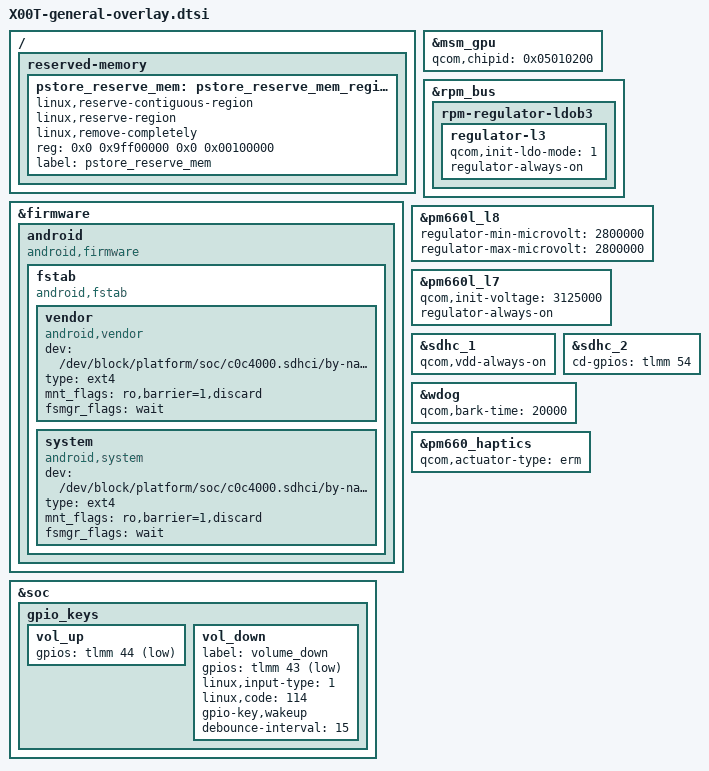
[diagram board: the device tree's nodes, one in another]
/* SPDX-License-Identifier: GPL-2.0 */

/ {
	reserved-memory {
		pstore_reserve_mem: pstore_reserve_mem_region@0 {
				linux,reserve-contiguous-region;
				linux,reserve-region;
				linux,remove-completely;
				reg = <0x0 0x9ff00000 0x0 0x00100000>;
				label = "pstore_reserve_mem";
		};
	};
};

&firmware {
	android {
		compatible = "android,firmware";
		fstab {
			compatible = "android,fstab";
			vendor {
				compatible = "android,vendor";
				dev = "/dev/block/platform/soc/c0c4000.sdhci/by-name/vendor";
				type = "ext4";
				mnt_flags = "ro,barrier=1,discard";
				fsmgr_flags = "wait";
				status = "ok";
			};
			system {
				compatible = "android,system";
				dev = "/dev/block/platform/soc/c0c4000.sdhci/by-name/system";
				type = "ext4";
				mnt_flags = "ro,barrier=1,discard";
				fsmgr_flags = "wait";
				status = "ok";
			};
		};	
	};
};

&msm_gpu {
	qcom,chipid = <0x05010200>;	
};	

&rpm_bus {
	rpm-regulator-ldob3 {
		regulator-l3 {
			qcom,init-ldo-mode = <1>;
			regulator-always-on;
		};
	};
};

&pm660l_l8 {
	regulator-min-microvolt = <2800000>;
	regulator-max-microvolt = <2800000>;
};

&pm660l_l7 {
	/delete-property/ parent-supply;

	qcom,init-voltage = <3125000>;
	regulator-always-on;
};

&sdhc_1 {
	qcom,vdd-always-on;
};

&sdhc_2 {
	cd-gpios = <&tlmm 54 0x0>;
};

&wdog {
	qcom,bark-time = <20000>;
};

&pm660_haptics {
	qcom,actuator-type = "erm";
};

&soc {
	gpio_keys {
		vol_up {
			gpios = <&tlmm 44 0x1>;
		};

		vol_down {
			label = "volume_down";
			gpios = <&tlmm 43 0x1>;
			linux,input-type = <1>;
			linux,code = <114>;
			gpio-key,wakeup;
			debounce-interval = <15>;
		};
	};
};	
